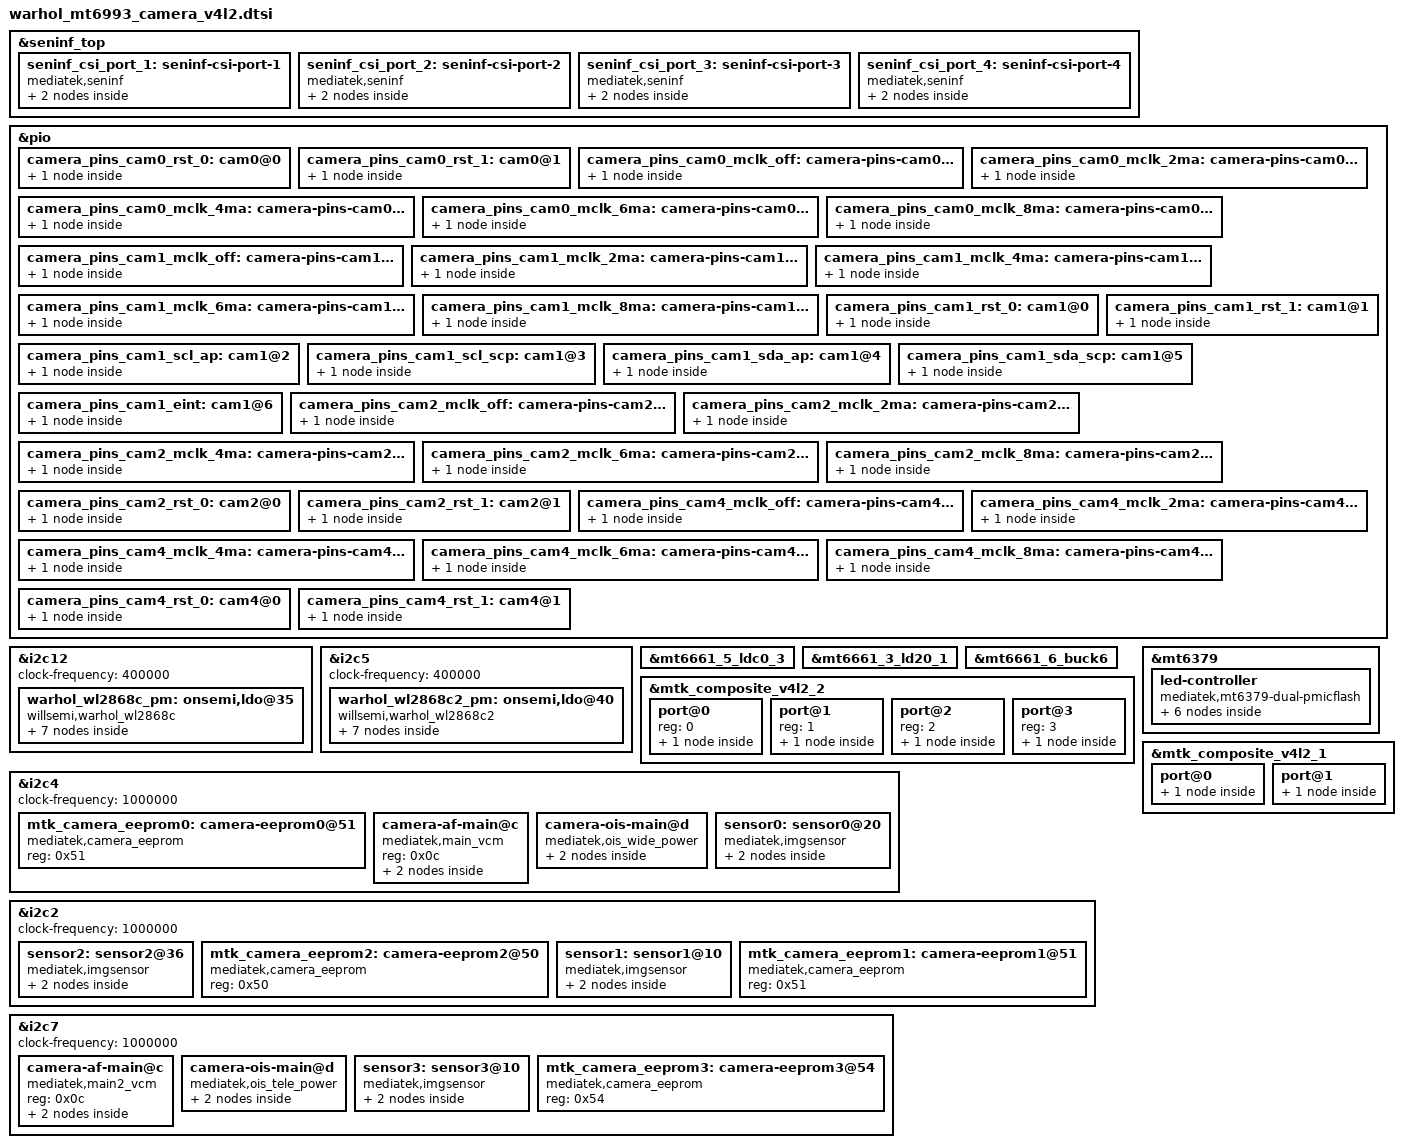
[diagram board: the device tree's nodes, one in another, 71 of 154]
// SPDX-License-Identifier: GPL-2.0
/* Copyright (c) 2023 MediaTek Inc. */
#include <dt-bindings/clock/mt6993-clk.h>
#include <dt-bindings/pinctrl/mt6993-pinfunc.h>
#include <dt-bindings/pinctrl/mt6667-pinfunc.h>
#include <dt-bindings/leds/common.h>
#include <dt-bindings/mfd/mt6379.h>


&seninf_top {
		seninf_csi_port_1: seninf-csi-port-1 {
			compatible = "mediatek,seninf";
			csi-port = "1";

			nvmem-cells = <&csi_efuse1>;
			nvmem-cell-names = "rg_csi";

			port {
				seninf_csi_port_1_in: endpoint {
					remote-endpoint = <&sensor2_out>;
				};
			};
		};

		seninf_csi_port_2: seninf-csi-port-2 {
			compatible = "mediatek,seninf";
			csi-port = "2";

			nvmem-cells = <&csi_efuse2>;
			nvmem-cell-names = "rg_csi";

			port {
				seninf_csi_port_2_in: endpoint {
					remote-endpoint = <&sensor1_out>;
				};
			};
		};

		seninf_csi_port_3: seninf-csi-port-3 {
			compatible = "mediatek,seninf";
			csi-port = "3";

			nvmem-cells = <&csi_efuse3>;
			nvmem-cell-names = "rg_csi";

			port {
				seninf_csi_port_3_in: endpoint {
					remote-endpoint = <&sensor0_out>;
				};
			};
		};

		seninf_csi_port_4: seninf-csi-port-4 {
			compatible = "mediatek,seninf";
			csi-port = "4";

			nvmem-cells = <&csi_efuse4>;
			nvmem-cell-names = "rg_csi";

			port {
				seninf_csi_port_4_in: endpoint {
					remote-endpoint = <&sensor3_out>;
				};
			};
		};

};

&pio {
	camera_pins_cam0_rst_0: cam0@0 {
		pins-cmd-dat {
			pinmux = <PINMUX_GPIO206__FUNC_GPIO206>;
			slew-rate = <1>;
			output-low;
		};
	};

	camera_pins_cam0_rst_1: cam0@1 {
		pins-cmd-dat {
			pinmux = <PINMUX_GPIO206__FUNC_GPIO206>;
			slew-rate = <1>;
			output-high;
		};
	};

	camera_pins_cam0_mclk_off: camera-pins-cam0-mclk-off {
		pins-cmd-dat {
			pinmux = <PINMUX_GPIO73__FUNC_GPIO73>;
			drive-strength = <1>;
		};
	};

	camera_pins_cam0_mclk_2ma: camera-pins-cam0-mclk-2ma {
		pins-cmd-dat {
			pinmux = <PINMUX_GPIO73__FUNC_CMMCLK1>;
			drive-strength = <0>;
		};
	};

	camera_pins_cam0_mclk_4ma: camera-pins-cam0-mclk-4ma {
		pins-cmd-dat {
			pinmux = <PINMUX_GPIO73__FUNC_CMMCLK1>;
			drive-strength = <1>;
		};
	};

	camera_pins_cam0_mclk_6ma: camera-pins-cam0-mclk-6ma {
		pins-cmd-dat {
			pinmux = <PINMUX_GPIO73__FUNC_CMMCLK1>;
			drive-strength = <2>;
		};
	};

	camera_pins_cam0_mclk_8ma: camera-pins-cam0-mclk-8ma {
		pins-cmd-dat {
			pinmux = <PINMUX_GPIO73__FUNC_CMMCLK1>;
			drive-strength = <3>;
		};
	};
	camera_pins_cam1_mclk_off: camera-pins-cam1-mclk-off {
		pins-cmd-dat {
			pinmux = <PINMUX_GPIO72__FUNC_GPIO72>;
			drive-strength = <1>;
		};
	};
	camera_pins_cam1_mclk_2ma: camera-pins-cam1-mclk-2ma {
		pins-cmd-dat {
			pinmux = <PINMUX_GPIO72__FUNC_CMMCLK0>;
			drive-strength = <0>;
		};
	};
	camera_pins_cam1_mclk_4ma: camera-pins-cam1-mclk-4ma {
		pins-cmd-dat {
			pinmux = <PINMUX_GPIO72__FUNC_CMMCLK0>;
			drive-strength = <1>;
		};
	};
	camera_pins_cam1_mclk_6ma: camera-pins-cam1-mclk-6ma {
		pins-cmd-dat {
			pinmux = <PINMUX_GPIO72__FUNC_CMMCLK0>;
			drive-strength = <2>;
		};
	};
	camera_pins_cam1_mclk_8ma: camera-pins-cam1-mclk-8ma {
		pins-cmd-dat {
			pinmux = <PINMUX_GPIO72__FUNC_CMMCLK0>;
			drive-strength = <3>;
		};
	};
	camera_pins_cam1_rst_0: cam1@0 {
		pins-cmd-dat {
			pinmux = <PINMUX_GPIO205__FUNC_GPIO205>;
			slew-rate = <1>;
			output-low;
		};
	};
	camera_pins_cam1_rst_1: cam1@1 {
		pins-cmd-dat {
			pinmux = <PINMUX_GPIO205__FUNC_GPIO205>;
			slew-rate = <1>;
			output-high;
		};
	};
	camera_pins_cam1_scl_ap: cam1@2 {
		pins-cmd-dat {
			pinmux = <PINMUX_GPIO172__FUNC_SCL2>;
		};
	};
	camera_pins_cam1_scl_scp: cam1@3 {
		pins-cmd-dat {
			pinmux = <PINMUX_GPIO172__FUNC_SCP_SCL8>;
		};
	};
	camera_pins_cam1_sda_ap: cam1@4 {
		pins-cmd-dat {
			pinmux = <PINMUX_GPIO173__FUNC_SDA2>;
		};
	};
	camera_pins_cam1_sda_scp: cam1@5 {
		pins-cmd-dat {
			pinmux = <PINMUX_GPIO173__FUNC_SCP_SDA8>;
		};
	};
	camera_pins_cam1_eint: cam1@6 {
		pins-cmd-dat {
			pinmux = <PINMUX_GPIO48__FUNC_GPIO48>;
			bias-pull-up;
			input-enable;
		};
	};
	camera_pins_cam2_mclk_off: camera-pins-cam2-mclk-off {
		pins-cmd-dat {
			pinmux = <PINMUX_GPIO208__FUNC_GPIO208>;
			drive-strength = <1>;
		};
	};
	camera_pins_cam2_mclk_2ma: camera-pins-cam2-mclk-2ma {
		pins-cmd-dat {
			pinmux = <PINMUX_GPIO208__FUNC_CMMCLK4>;
			drive-strength = <0>;
		};
	};
	camera_pins_cam2_mclk_4ma: camera-pins-cam2-mclk-4ma {
		pins-cmd-dat {
			pinmux = <PINMUX_GPIO208__FUNC_CMMCLK4>;
			drive-strength = <1>;
		};
	};
	camera_pins_cam2_mclk_6ma: camera-pins-cam2-mclk-6ma {
		pins-cmd-dat {
			pinmux = <PINMUX_GPIO208__FUNC_CMMCLK4>;
			drive-strength = <2>;
		};
	};
	camera_pins_cam2_mclk_8ma: camera-pins-cam2-mclk-8ma {
		pins-cmd-dat {
			pinmux = <PINMUX_GPIO208__FUNC_CMMCLK4>;
			drive-strength = <3>;
		};
	};
	camera_pins_cam2_rst_0: cam2@0 {
		pins-cmd-dat {
			pinmux = <PINMUX_GPIO207__FUNC_GPIO207>;
			slew-rate = <1>;
			output-low;
		};
	};
	camera_pins_cam2_rst_1: cam2@1 {
		pins-cmd-dat {
			pinmux = <PINMUX_GPIO207__FUNC_GPIO207>;
			slew-rate = <1>;
			output-high;
		};
	};
	camera_pins_cam4_mclk_off: camera-pins-cam4-mclk-off {
		pins-cmd-dat {
			pinmux = <PINMUX_GPIO210__FUNC_GPIO210>;
			drive-strength = <1>;
		};
	};
	camera_pins_cam4_mclk_2ma: camera-pins-cam4-mclk-2ma {
		pins-cmd-dat {
			pinmux = <PINMUX_GPIO210__FUNC_CMMCLK6>;
			drive-strength = <0>;
		};
	};
	camera_pins_cam4_mclk_4ma: camera-pins-cam4-mclk-4ma {
		pins-cmd-dat {
			pinmux = <PINMUX_GPIO210__FUNC_CMMCLK6>;
			drive-strength = <1>;
		};
	};
	camera_pins_cam4_mclk_6ma: camera-pins-cam4-mclk-6ma {
		pins-cmd-dat {
			pinmux = <PINMUX_GPIO210__FUNC_CMMCLK6>;
			drive-strength = <2>;
		};
	};
	camera_pins_cam4_mclk_8ma: camera-pins-cam4-mclk-8ma {
		pins-cmd-dat {
			pinmux = <PINMUX_GPIO210__FUNC_CMMCLK6>;
			drive-strength = <3>;
		};
	};
	camera_pins_cam4_rst_0: cam4@0 {
		pins-cmd-dat {
			pinmux = <PINMUX_GPIO189__FUNC_GPIO189>;
			slew-rate = <1>;
			output-low;
		};
	};
	camera_pins_cam4_rst_1: cam4@1 {
		pins-cmd-dat {
			pinmux = <PINMUX_GPIO189__FUNC_GPIO189>;
			slew-rate = <1>;
			output-high;
		};
	};
};

&i2c12 {
	status = "okay";
	clock-frequency = <400000>;
/*u7800*/
	warhol_wl2868c_pm:onsemi,ldo@35 {
		compatible = "willsemi,warhol_wl2868c";
		reg = <0x35>;/*slave address*/
		index = <0>;

		warhol_wl2868c_l1:on,wl2868c@0{
			offset = /bits/ 16 <0x0000>;
			regulator-name ="warhol_wl2868c-l1";
			regulator-min-microvolt = <496000>;
			regulator-max-microvolt = <2048000>;
			min-dropout-voltage = <225000>;
			init-voltage = <1200000>;
			iout_ua = <650000>;
		};

		warhol_wl2868c_l2:on,wl2868c@1{
			offset = /bits/ 16 <0x0001>;
			regulator-name ="warhol_wl2868c-l2";
			regulator-min-microvolt = <496000>;
			regulator-max-microvolt = <2048000>;
			min-dropout-voltage = <225000>;
			init-voltage = <1200000>;
			iout_ua = <650000>;
		};

		warhol_wl2868c_l3:on,wl2868c@2{
			offset = /bits/ 16 <0x0002>;
			regulator-name ="warhol_wl2868c-l3";
			regulator-min-microvolt = <1372000>;
			regulator-max-microvolt = <3412000>;
			min-dropout-voltage = <200000>;
			init-voltage = <2800000>;
			iout_ua = <650000>;
		};

		warhol_wl2868c_l4:on,wl2868c@3{
			offset = /bits/ 16 <0x0003>;
			regulator-name ="warhol_wl2868c-l4";
			regulator-min-microvolt = <1372000>;
			regulator-max-microvolt = <3412000>;
			min-dropout-voltage = <200000>;
			init-voltage = <2800000>;
			iout_ua = <650000>;
		};

		warhol_wl2868c_l5:on,wl2868c@4{
			offset = /bits/ 16 <0x0004>;
			regulator-name ="warhol_wl2868c-l5";
			regulator-min-microvolt = <1372000>;
			regulator-max-microvolt = <3412000>;
			min-dropout-voltage = <300000>;
			init-voltage = <2800000>;
			iout_ua = <650000>;
		};

		warhol_wl2868c_l6:on,wl2868c@5{
			offset = /bits/ 16 <0x0005>;
			regulator-name ="warhol_wl2868c-l6";
			regulator-min-microvolt = <1372000>;
			regulator-max-microvolt = <3412000>;
			min-dropout-voltage = <300000>;
			init-voltage = <2800000>;
			iout_ua = <650000>;
		};

		warhol_wl2868c_l7:on,wl2868c@6{
			offset = /bits/ 16 <0x0006>;
			regulator-name ="warhol_wl2868c-l7";
			regulator-min-microvolt = <1372000>;
			regulator-max-microvolt = <3412000>;
			min-dropout-voltage = <300000>;
			init-voltage = <2800000>;
			iout_ua = <650000>;
		};
	};

};

&i2c5 {
	status = "okay";
	clock-frequency = <400000>;


/*u7802*/
	warhol_wl2868c2_pm:onsemi,ldo@40 {
		compatible = "willsemi,warhol_wl2868c2";
		reg = <0x40>;/*slave address*/
		index = <1>;

		warhol_wl2868c2_l1:on,wl2868c2@0{
			offset = /bits/ 16 <0x0000>;
			regulator-name ="warhol_wl2868c2-l1";
			regulator-min-microvolt = <496000>;
			regulator-max-microvolt = <2048000>;
			min-dropout-voltage = <225000>;
			init-voltage = <1200000>;
			iout_ua = <650000>;
		};

		warhol_wl2868c2_l2:on,wl2868c2@1{
			offset = /bits/ 16 <0x0001>;
			regulator-name ="warhol_wl2868c2-l2";
			regulator-min-microvolt = <496000>;
			regulator-max-microvolt = <2048000>;
			min-dropout-voltage = <225000>;
			init-voltage = <1200000>;
			iout_ua = <650000>;
		};

		warhol_wl2868c2_l3:on,wl2868c2@2{
			offset = /bits/ 16 <0x0002>;
			regulator-name ="warhol_wl2868c2-l3";
			regulator-min-microvolt = <1372000>;
			regulator-max-microvolt = <3412000>;
			min-dropout-voltage = <200000>;
			init-voltage = <2800000>;
			iout_ua = <650000>;
		};

		warhol_wl2868c2_l4:on,wl2868c2@3{
			offset = /bits/ 16 <0x0003>;
			regulator-name ="warhol_wl2868c2-l4";
			regulator-min-microvolt = <1372000>;
			regulator-max-microvolt = <3412000>;
			min-dropout-voltage = <200000>;
			init-voltage = <2800000>;
			iout_ua = <650000>;
		};

		warhol_wl2868c2_l5:on,wl2868c2@4{
			offset = /bits/ 16 <0x0004>;
			regulator-name ="warhol_wl2868c2-l5";
			regulator-min-microvolt = <1372000>;
			regulator-max-microvolt = <3412000>;
			min-dropout-voltage = <300000>;
			init-voltage = <2800000>;
			iout_ua = <650000>;
		};

		warhol_wl2868c2_l6:on,wl2868c2@5{
			offset = /bits/ 16 <0x0005>;
			regulator-name ="warhol_wl2868c2-l6";
			regulator-min-microvolt = <1372000>;
			regulator-max-microvolt = <3412000>;
			min-dropout-voltage = <300000>;
			init-voltage = <2800000>;
			iout_ua = <650000>;
		};

		warhol_wl2868c2_l7:on,wl2868c2@6{
			offset = /bits/ 16 <0x0006>;
			regulator-name ="warhol_wl2868c2-l7";
			regulator-min-microvolt = <1372000>;
			regulator-max-microvolt = <3412000>;
			min-dropout-voltage = <300000>;
			init-voltage = <2800000>;
			iout_ua = <650000>;
		};
	};
};

&mt6661_5_ldc0_3 {
	regulator-min-microvolt = <1800000>;
	regulator-max-microvolt = <1800000>;
};

&mt6661_3_ld20_1 {
	regulator-min-microvolt = <3300000>;
	regulator-max-microvolt = <3300000>;
};

&mt6661_6_buck6 {
	regulator-compatible = "BUCK6";
	regulator-name = "mt6661_6_buck6";
	regulator-min-microvolt = <400000>;
	regulator-max-microvolt = <1200000>;
	regulator-enable-ramp-delay = <180>;
	regulator-allowed-modes = <0 1 2>;
	regulator-always-on;
	regulator-allow-set-load;
};

&mtk_composite_v4l2_2 {
	#address-cells = <1>;
	#size-cells = <0>;
	port@0 {
		reg = <0>;
		main_af_wide_endpoint: endpoint {
			remote-endpoint = <&main_af_wide>;
		};
	};
	port@1 {
		reg = <1>;
		main_af_tele_endpoint: endpoint {
			remote-endpoint = <&main_af_tele>;
		};
    };
	port@2 {
		reg = <2>;
		main_ois_cam1_endpoint: endpoint {
			remote-endpoint = <&main_ois_cam1>;
		};
	};
	port@3 {
		reg = <3>;
		main_ois_cam2_endpoint: endpoint {
			remote-endpoint = <&main_ois_cam2>;
		};
	};
};

&i2c4 {
	status = "okay";
	clock-frequency = <1000000>;

	mtk_camera_eeprom0:camera-eeprom0@51 {
		compatible = "mediatek,camera_eeprom";
		reg = <0x51>;
		status = "okay";
	};

	camera-af-main@c {
		compatible = "mediatek,main_vcm";
		reg = <0x0c>;
		port {
			main_af_wide: endpoint {
				remote-endpoint = <&main_af_wide_endpoint>;
			};
		};
	};
	/* wide ois */
	camera-ois-main@d {
		compatible = "mediatek,ois_wide_power";
		reg = <0x0d>;
		vin-supply = <&warhol_wl2868c2_l4>;
		port {
			main_ois_cam1: endpoint {
				remote-endpoint = <&main_ois_cam1_endpoint>;
			};
		};
	};

	sensor0: sensor0@20 {
		compatible = "mediatek,imgsensor";
		sensor-names = "warholovx9500wide_mipi_raw";
		reg = <0x20 0 0>;

		#thermal-sensor-cells = <0>;

		pinctrl-names = "mclk_off",
				"mclk_2mA",
				"mclk_4mA",
				"mclk_6mA",
				"mclk_8mA",
				"rst_low",
				"rst_high";
		pinctrl-0 = <&camera_pins_cam0_mclk_off>;
		pinctrl-1 = <&camera_pins_cam0_mclk_2ma>;
		pinctrl-2 = <&camera_pins_cam0_mclk_4ma>;
		pinctrl-3 = <&camera_pins_cam0_mclk_6ma>;
		pinctrl-4 = <&camera_pins_cam0_mclk_8ma>;
		pinctrl-5 = <&camera_pins_cam0_rst_0>;
		pinctrl-6 = <&camera_pins_cam0_rst_1>;

		avdd-supply =  <&warhol_wl2868c_l6>;
		avdd1-supply = <&warhol_wl2868c_l4>;
		dvdd-supply = <&warhol_wl2868c_l2>;
		dovdd-supply = <&mt6661_5_ldc0_3>;
		afvdd-supply = <&warhol_wl2868c2_l3>;

		clocks = <&cksys_top_clk CKSYS_TOP_UNIVPLL_192M_D32>,
			<&cksys_top_clk CKSYS_TOP_UNIVPLL_192M_D16>,
			<&cksys_top_clk CKSYS_VLP_F26M_CK_D2>,
			<&cksys_top_clk CKSYS_TOP_UNIVPLL_192M_D10>,
			<&cksys_top_clk CKSYS_TOP_UNIVPLL_192M_D8>,
			<&cksys_top_clk CKSYS_TOP_UNIVPLL_D6_D16>,
			<&cksys_vlp_clk CKSYS_VLP_OSC3>,
			<&cksys_top_clk CKSYS_TOP_UNIVPLL_D6_D8>,
			<&cksys_vlp_clk VLP_CAMTG1_SEL>;

		clock-names = "6", "12", "13", "19.2", "24", "26", "26_ulposc", "52", "mclk";


		status = "okay";
		port {
			sensor0_out: endpoint {
				remote-endpoint = <&seninf_csi_port_3_in>;
			};
		};
	};
};

&i2c2 {
	status = "okay";
	clock-frequency = <1000000>;

	sensor2: sensor2@36 {
		compatible = "mediatek,imgsensor";
		sensor-names = "warholov13bultra_mipi_raw";
		reg = <0x36>;

		#thermal-sensor-cells = <0>;

		pinctrl-names = "mclk_off",
				"mclk_2mA",
				"mclk_4mA",
				"mclk_6mA",
				"mclk_8mA",
				"rst_low",
				"rst_high";


		pinctrl-0 = <&camera_pins_cam2_mclk_off>;
		pinctrl-1 = <&camera_pins_cam2_mclk_2ma>;
		pinctrl-2 = <&camera_pins_cam2_mclk_4ma>;
		pinctrl-3 = <&camera_pins_cam2_mclk_6ma>;
		pinctrl-4 = <&camera_pins_cam2_mclk_8ma>;
		pinctrl-5 = <&camera_pins_cam2_rst_0>;
		pinctrl-6 = <&camera_pins_cam2_rst_1>;

		avdd-supply = <&warhol_wl2868c_l7>;
		dvdd-supply = <&warhol_wl2868c_l1>;
		dovdd-supply = <&mt6661_5_ldc0_3>;

		clocks = <&cksys_top_clk CKSYS_TOP_UNIVPLL_192M_D32>,
			<&cksys_top_clk CKSYS_TOP_UNIVPLL_192M_D16>,
			<&cksys_top_clk CKSYS_VLP_F26M_CK_D2>,
			<&cksys_top_clk CKSYS_TOP_UNIVPLL_192M_D10>,
			<&cksys_top_clk CKSYS_TOP_UNIVPLL_192M_D8>,
			<&cksys_top_clk CKSYS_TOP_UNIVPLL_D6_D16>,
			<&cksys_top_clk CKSYS_TOP_OSC_D20>,
			<&cksys_top_clk CKSYS_TOP_UNIVPLL_D6_D8>,
			<&cksys_vlp_clk VLP_CAMTG4_SEL>;
		clock-names = "6", "12", "13", "19.2", "24", "26", "26_ulposc", "52", "mclk";

		status = "okay";
		port {
			sensor2_out: endpoint {
				remote-endpoint = <&seninf_csi_port_1_in>;
			};
		};
	};

	mtk_camera_eeprom2:camera-eeprom2@50 {
		compatible = "mediatek,camera_eeprom";
		reg = <0x50>;
		status = "okay";
	};

	sensor1: sensor1@10 {
		compatible = "mediatek,imgsensor";
		sensor-names = "warhols5kkdsfront_mipi_raw";
		reg = <0x10>;

		pinctrl-names = "mclk1_off",
				"mclk1_2mA",
				"mclk1_4mA",
				"mclk1_6mA",
				"mclk1_8mA",
				"rst_low",
				"rst_high",
				"scl_ap",
				"scl_scp",
				"sda_ap",
				"sda_scp",
				"eint";
		pinctrl-0 = <&camera_pins_cam1_mclk_off>;
		pinctrl-1 = <&camera_pins_cam1_mclk_2ma>;
		pinctrl-2 = <&camera_pins_cam1_mclk_4ma>;
		pinctrl-3 = <&camera_pins_cam1_mclk_6ma>;
		pinctrl-4 = <&camera_pins_cam1_mclk_8ma>;
		pinctrl-5 = <&camera_pins_cam1_rst_0>;
		pinctrl-6 = <&camera_pins_cam1_rst_1>;
		pinctrl-7 = <&camera_pins_cam1_scl_ap>;
		pinctrl-8 = <&camera_pins_cam1_scl_scp>;
		pinctrl-9 = <&camera_pins_cam1_sda_ap>;
		pinctrl-10 = <&camera_pins_cam1_sda_scp>;
		pinctrl-11 = <&camera_pins_cam1_eint>;


		avdd-supply = <&warhol_wl2868c_l3>;
		dvdd-supply = <&warhol_wl2868c2_l2>;
		dovdd-supply = <&mt6661_5_ldc0_3>;

		clocks = <&cksys_top_clk CKSYS_TOP_UNIVPLL_192M_D32>,
			<&cksys_top_clk CKSYS_TOP_UNIVPLL_192M_D16>,
			<&cksys_top_clk CKSYS_VLP_F26M_CK_D2>,
			<&cksys_top_clk CKSYS_TOP_UNIVPLL_192M_D10>,
			<&cksys_top_clk CKSYS_TOP_UNIVPLL_192M_D8>,
			<&cksys_top_clk CKSYS_TOP_UNIVPLL_D6_D16>,
			<&cksys_vlp_clk CKSYS_VLP_OSC3>,
			<&cksys_top_clk CKSYS_TOP_UNIVPLL_D6_D8>,
			<&cksys_vlp_clk VLP_CAMTG0_SEL>;
		clock-names = "6", "12", "13", "19.2", "24", "26", "26_ulposc", "52", "mclk";

		status = "okay";
		port {
			sensor1_out: endpoint {
				remote-endpoint = <&seninf_csi_port_2_in>;
			};
		};
	};

	mtk_camera_eeprom1:camera-eeprom1@51 {
		compatible = "mediatek,camera_eeprom";
		reg = <0x51>;
		status = "okay";
	};
};

&i2c7 {
	status = "okay";
	clock-frequency = <1000000>;

	camera-af-main@c {
		compatible = "mediatek,main2_vcm";
		reg = <0x0c>;
		port {
			main_af_tele: endpoint {
				remote-endpoint = <&main_af_tele_endpoint>;
			};
		};
	};
	/* tele ois */
	camera-ois-main@d {
		compatible = "mediatek,ois_tele_power";
		reg = <0x0d>;
		vin-supply = <&warhol_wl2868c2_l5>;
		port {
			main_ois_cam2: endpoint {
				remote-endpoint = <&main_ois_cam2_endpoint>;
			};
		};
	};

	sensor3: sensor3@10 {
		compatible = "mediatek,imgsensor";
		sensor-names = "warhols5kjn5tele_mipi_raw";
		reg = <0x26>;

		#thermal-sensor-cells = <0>;

		pinctrl-names = "mclk_off",
				"mclk_2mA",
				"mclk_4mA",
				"mclk_6mA",
				"mclk_8mA",
				"rst_low",
				"rst_high";

		pinctrl-0 = <&camera_pins_cam4_mclk_off>;
		pinctrl-1 = <&camera_pins_cam4_mclk_2ma>;
		pinctrl-2 = <&camera_pins_cam4_mclk_4ma>;
		pinctrl-3 = <&camera_pins_cam4_mclk_6ma>;
		pinctrl-4 = <&camera_pins_cam4_mclk_8ma>;
		pinctrl-5 = <&camera_pins_cam4_rst_0>;
		pinctrl-6 = <&camera_pins_cam4_rst_1>;


		avdd-supply = <&warhol_wl2868c_l5>;
		dvdd-supply = <&warhol_wl2868c2_l1>;
		dovdd-supply = <&mt6661_5_ldc0_3>;
		afvdd-supply = <&mt6661_3_ld20_1>;

		clocks = <&cksys_top_clk CKSYS_TOP_UNIVPLL_192M_D32>,
			<&cksys_top_clk CKSYS_TOP_UNIVPLL_192M_D16>,
			<&cksys_top_clk CKSYS_VLP_F26M_CK_D2>,
			<&cksys_top_clk CKSYS_TOP_UNIVPLL_192M_D10>,
			<&cksys_top_clk CKSYS_TOP_UNIVPLL_192M_D8>,
			<&cksys_top_clk CKSYS_TOP_UNIVPLL_D6_D16>,
			<&cksys_vlp_clk CKSYS_VLP_OSC3>,
			<&cksys_top_clk CKSYS_TOP_UNIVPLL_D6_D8>,
			<&cksys_vlp_clk VLP_CAMTG6_SEL>;
		clock-names = "6", "12", "13", "19.2", "24", "26", "26_ulposc", "52", "mclk";

		status = "okay";
		port {
			sensor3_out: endpoint {
				remote-endpoint = <&seninf_csi_port_4_in>;
			};
		};
	};

	mtk_camera_eeprom3:camera-eeprom3@54 {
		compatible = "mediatek,camera_eeprom";
		reg = <0x54>;
		status = "okay";
	};
};

&mt6379{
	led-controller {
		compatible = "mediatek,mt6379-dual-pmicflash";
		#address-cells = <1>;
		#size-cells = <0>;
		interrupts = <MT6379_EVT_FLED_LVF> , <MT6379_EVT_FL_BUBO_VIN_THRO>,
					<MT6379_EVT_FL_THERMAL_THRO>, <MT6379_EVT_FL_BUBO_IL_THRO>,
					<MT6379_EVT_FLED3_SHORT>, <MT6379_EVT_FLED2_SHORT>,
					<MT6379_EVT_FLED1_SHORT>;
		interrupt-names = "fled_lvf", "fled_bubo_vin_thro",
					"fled_thermal_thro", "fled_bubo_il_thro",
					"fled3_short", "fled2_short",
					"fled1_short";
		led@0 {
			reg = <0>;
			function = LED_FUNCTION_FLASH;
			color = <LED_COLOR_ID_WHITE>;
			function-enumerator = <1>;
			led-max-microamp = <600000>;
			flash-max-microamp = <1500000>;
			type = <0>;
			ct = <0>;
			part = <0>;
			port@0 {
				fl_core_0: endpoint {
					remote-endpoint = <&flashlight_0>;
				};
			};
		};
		led@1 {
			reg = <1>;
			function = LED_FUNCTION_FLASH;
			color = <LED_COLOR_ID_WHITE>;
			function-enumerator = <2>;
			led-max-microamp = <600000>;
			flash-max-microamp = <1500000>;
			type = <0>;
			ct = <1>;
			part = <0>;
			port@1 {
				fl_core_1: endpoint {
					remote-endpoint = <&flashlight_1>;
				};
			};
		};
	};
};

&mtk_composite_v4l2_1 {
	port@0 {
			flashlight_0: endpoint {
				remote-endpoint = <&fl_core_0>;
			};
	};
	port@1 {
			flashlight_1: endpoint {
				remote-endpoint = <&fl_core_1>;
			};
	};
};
